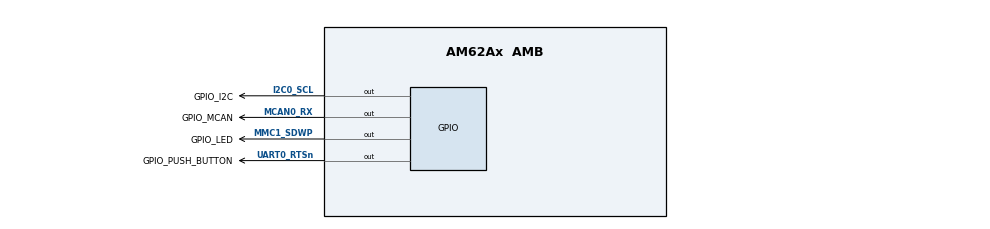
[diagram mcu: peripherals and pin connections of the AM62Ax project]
/**
 * @cliArgs --device "AM62Ax" --package "AMB" --part "Default" --context "a53ss0-0" --product "MCU_PLUS_SDK@07.03.01"
 * @versions {"tool":"1.24.1+4189"}
 */

/**
 * Import the modules used in this configuration.
 */
const gpio       = scripting.addModule("/drivers/gpio/gpio", {}, false);
const gpio1      = gpio.addInstance();
const gpio2      = gpio.addInstance();
const gpio3      = gpio.addInstance();
const gpio4      = gpio.addInstance();

const ipc        = scripting.addModule("/drivers/ipc/ipc");
const debug_log  = scripting.addModule("/kernel/dpl/debug_log");
const mmu_armv8  = scripting.addModule("/kernel/dpl/mmu_armv8", {}, false);
const mmu_armv81 = mmu_armv8.addInstance();
const mmu_armv82 = mmu_armv8.addInstance();
const mmu_armv83 = mmu_armv8.addInstance();
const mmu_armv84 = mmu_armv8.addInstance();
const mmu_armv85 = mmu_armv8.addInstance();

/**
 * Write custom configuration values to the imported modules.
 */
ipc.enableLinuxIpc = false;
ipc.mcu_r5fss0_0   = "notify";
ipc.r5fss0_0       = "notify";
ipc.c75ss0_0       = "notify";

gpio1.$name        = "GPIO_LED";
gpio1.pinDir       = "OUTPUT";
gpio1.GPIO.gpioPin.$assign = "MMC1_SDWP";

gpio2.$name        = "GPIO_PUSH_BUTTON";
gpio2.GPIO.gpioPin.$assign = "UART0_RTSn";

gpio3.$name        = "GPIO_I2C";
gpio3.pinDir       = "OUTPUT";
gpio3.GPIO.gpioPin.$assign = "I2C0_SCL";

gpio4.$name        = "GPIO_MCAN";
gpio4.pinDir       = "OUTPUT";
gpio4.GPIO.gpioPin.$assign = "MCAN0_RX";

debug_log.enableCssLog       = false;
debug_log.enableSharedMemLog = true;

mmu_armv81.size  = 0x80000000;
mmu_armv81.$name = "SOC_MEM_REGION";

mmu_armv82.vAddr     = 0x80000000;
mmu_armv82.pAddr     = 0x80000000;
mmu_armv82.size      = 0x2000000;
mmu_armv82.attribute = "MAIR7";
mmu_armv82.$name     = "DDR_REGION";

mmu_armv83.$name     = "LOG_SHM_MEM";
mmu_armv83.vAddr     = 0xA1000000;
mmu_armv83.pAddr     = 0xA1000000;
mmu_armv83.size      = 0x40000;
mmu_armv83.attribute = "MAIR4";

mmu_armv84.$name     = "VRING_REGION";
mmu_armv84.vAddr     = 0x9B000000;
mmu_armv84.pAddr     = 0x9B000000;
mmu_armv84.size      = 0x4000000;
mmu_armv84.attribute = "MAIR4";

mmu_armv85.$name     = "AMP_SHM";
mmu_armv85.vAddr     = 0x99000000;
mmu_armv85.pAddr     = 0x99000000;
mmu_armv85.size      = 0x4000;
mmu_armv85.attribute = "MAIR7";

/**
 * Pinmux solution for unlocked pins/peripherals. This ensures that minor changes to the automatic solver in a future
 * version of the tool will not impact the pinmux you originally saw.  These lines can be completely deleted in order to
 * re-solve from scratch.
 */
